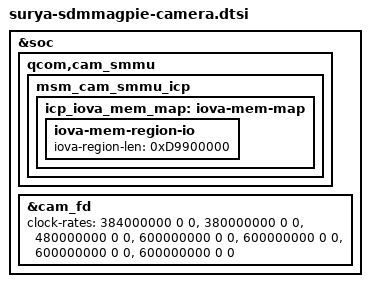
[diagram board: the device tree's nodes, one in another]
&soc {
	qcom,cam_smmu {
		msm_cam_smmu_icp {
			icp_iova_mem_map: iova-mem-map {
				iova-mem-region-io {
					iova-region-len = <0xD9900000>;
                };
            };
        };
    };
    &cam_fd {
        clock-rates =
			    <384000000 0 0>,
			    <380000000 0 0>,
			    <480000000 0 0>,
			    <600000000 0 0>,
			    <600000000 0 0>,
			    <600000000 0 0>,
			    <600000000 0 0>;
    }
};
